# N32F030 register map
File version: 1.0
Registers are 32-bit, read-write, reset 0x0 unless marked. A register's access mark holds for its fields unless they carry their own. Offsets are from the block's base; [hi:lo] are bit positions; {n}, {i} and the like mark numbered series.

## FMC — FMC Register Map
Base 0x5000C000
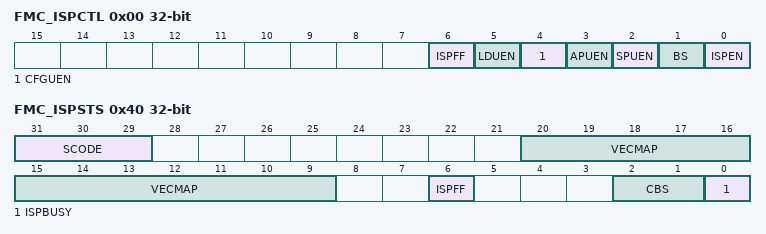
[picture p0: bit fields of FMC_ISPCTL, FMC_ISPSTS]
0x00 FMC_ISPCTL — ISP Control Register
  [6] ISPFF — ISP Fail Flag (Write Protect). This bit is set by hardware when a triggered ISP meets any of the following conditions: (1) APROM writes to itself if APUEN is set to 0. (2) LDROM writes to itself if LDUEN is set to 0. (3) SPROM writes to itself if SPUEN is set to 0. (4) CONFIG is erased/programmed if CFGUEN is set to 0. (5) Page Erase command at LOCK mode with ICE connection (6) Erase or Program command at brown-out detected (7) Destination address is illegal, such as over an available range. (8) Invalid ISP commands. Note: Write 1 to clear this bit to 0.
  [5] LDUEN — LDROM Update Enable Control (Write Protect)
    0=LDROM cannot be updated; 1=LDROM can be updated when the MCU runs in APROM
  [4] CFGUEN — CONFIG Update Enable Control (Write Protect). Writing this bit to 1 enables software to update CONFIG value by ISP register control procedure regardless of program code is running in APROM or LDROM.
    0=ISP update User Configuration Disabled; 1=ISP update User Configuration Enabled
  [3] APUEN — APROM Update Enable Control (Write Protect)
    0=APROM cannot be updated when chip runs in APROM; 1=APROM can be updated when chip runs in APROM
  [2] SPUEN — SPROM Update Enable Control (Write Protect)
    0=SPROM cannot be updated; 1=SPROM can be updated when the MCU runs in APROM
  [1] BS — Boot Select (Write Protect). Set/clear this bit to select next booting from LDROM/APROM, respectively. This bit also functions as chip booting status flag, which can be used to check where chip booted from. This bit is initiated with the inversed value of CBS in CONFIG0 after any reset is happened except CPU reset (CPURF is 1) or system reset (SYSRF) is happened.
    0=Boot from APROM; 1=Boot from LDROM
  [0] ISPEN — ISP Enable Control (Write Protect). Set this bit to enable ISP function.
    0=ISP function Disabled; 1=ISP function Enabled
0x04 FMC_ISPADDR — ISP Address Register
  [31:0] ISPADR — ISP Address. The NM1240 series supports word program only. ISPADR[1:0] must be kept 00 for ISP operation.
0x08 FMC_ISPDAT — ISP Data Register
  [31:0] ISPDAT — ISP Data. Write data to this register before ISP program operation. Read data from this register after ISP read operation.
0x0C FMC_ISPCMD — ISP Command Register
  [5:0] CMD — ISP Command. ISP commands are shown below:
    0=Read; 4=Read Unique ID; 11=Read Company ID (0xDA); 13=Read CRC32 Checksum Result After Calculating; 33=Program; 34=Page Erase; 45=Run Memory CRC32 Checksum Calculation; 46=Set Vector Page Re-Map
0x10 FMC_ISPTRG — ISP Trigger Register
  [0] ISPGO — ISP Start Trigger (Write Protect). Write 1 to start ISP operation and this bit will be cleared to 0 by hardware automatically when ISP operation is finished.
    0=ISP operation is finished; 1=ISP operation is progressed
0x14 FMC_DFBA ro reset 0xFFFFFFFF — Data Flash Start Address
  [31:0] DFBA — Data Flash Base Address. This register indicates Data Flash start address. It is a read only register. The Data Flash start address is defined by user. Since on chip flash erase unit is 512 bytes, it is mandatory to keep bit 8-0 as 0.
0x40 FMC_ISPSTS reset not defined — ISP Status Register
  [31:29] SCODE — Security Code Active Flag. This bit field set by hardware when detecting SPROM secured code is active at flash initiation, or software writes 1 to this bit to make secured code active; this bit is clear by SPROM page erase operation.
    0=SPROM0/1/2 secured code are inactive; 1=SPROM0 secured code is active; 2=SPROM1 secured code is active; 4=SPROM2 secured code is active; 7=SPROM0/1/2 Secured code are active
  [20:9] VECMAP ro — Vector Page Mapping Address (Read Only). The current flash address space 0x0000_0000~0x0000_01FF is mapping to address {VECMAP[11:0], 9'h000} ~ {VECMAP[11:0], 9'h1FF}.
  [6] ISPFF — ISP Fail Flag (Write Protect). This bit is set by hardware when a triggered ISP meets any of the following conditions: (1) APROM writes to itself if APUEN is set to 0. (2) LDROM writes to itself if LDUEN is set to 0. (3) SPROM writes to itself if SPUEN is set to 0. (4) CONFIG is erased/programmed if CFGUEN is set to 0. (5) Page Erase command at LOCK mode with ICE connection (6) Erase or Program command at brown-out detected (7) Destination address is illegal, such as over an available range. (8) Invalid ISP commands. Note: Write 1 to clear this bit to 0.
  [2:1] CBS ro — Config Boot Selection (Read Only). This is a mirror of CBS in CONFIG0.
  [0] ISPBUSY ro — ISP Start Trigger (Read Only). Write 1 to start ISP operation and this bit will be cleared to 0 by hardware automatically when ISP operation is finished. Note: This bit is the same with FMC_ISPTRG bit 0.
    0=ISP operation is finished; 1=ISP operation is progressed
0x50 FMC_CRCSEED reset 0xFFFFFFFF — ISP CRC Seed Register
  [31:0] CRCSEED — CRC Seed Data. This register was provided to be the initial value for CRC operation. Write data to this register before ISP CRC operation. Read data from this register after ISP CRC read operation.
0x54 FMC_CRCCV ro reset not defined — ISP CRC Current Value Register
  [31:0] CRCCV — CRC Current Value. This register provided current value of CRC during calculation.
